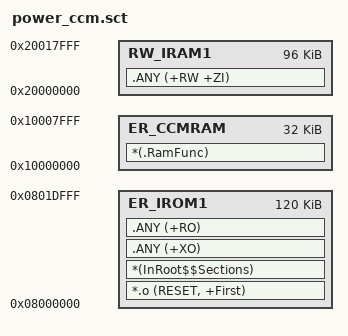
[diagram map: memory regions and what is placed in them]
; STM32G474RBT6 Custom Scatter File (CubeMX-safe: will not be overwritten by Generate Code)
; - Flash:     0x08000000 - 0x0801DFFF (120 KB; last 8 KB 0x0801E000-0x0801FFFF reserved for A/B params)
; - CCM SRAM:  0x10000000 - 0x10007FFF (32 KB zero-wait-state I-Bus/D-Bus for 100 kHz / 10 kHz control ISRs)
; - SRAM1+2:   0x20000000 - 0x20017FFF (96 KB DMA-accessible RAM; capped at 96 KB to avoid CCM alias at 0x20018000)

LR_IROM1 0x08000000 0x0001E000  {
  ER_IROM1 0x08000000 0x0001E000  {
    *.o (RESET, +First)
    *(InRoot$$Sections)
    .ANY (+XO)
    .ANY (+RO)
  }

  ; Zero-wait-state CCM SRAM: 100 kHz / 10 kHz critical control loops & ISRs
  ; Automatically copied from Flash into 0x10000000 by __main scatter-loader before main().
  ER_CCMRAM 0x10000000 0x00008000  {
    *(.RamFunc)
  }

  ; Main SRAM1 + SRAM2 (96 KB): stack, heap, DMA/ADC/USB buffers, globals
  RW_IRAM1 0x20000000 0x00018000  {
    .ANY (+RW +ZI)
  }
}
